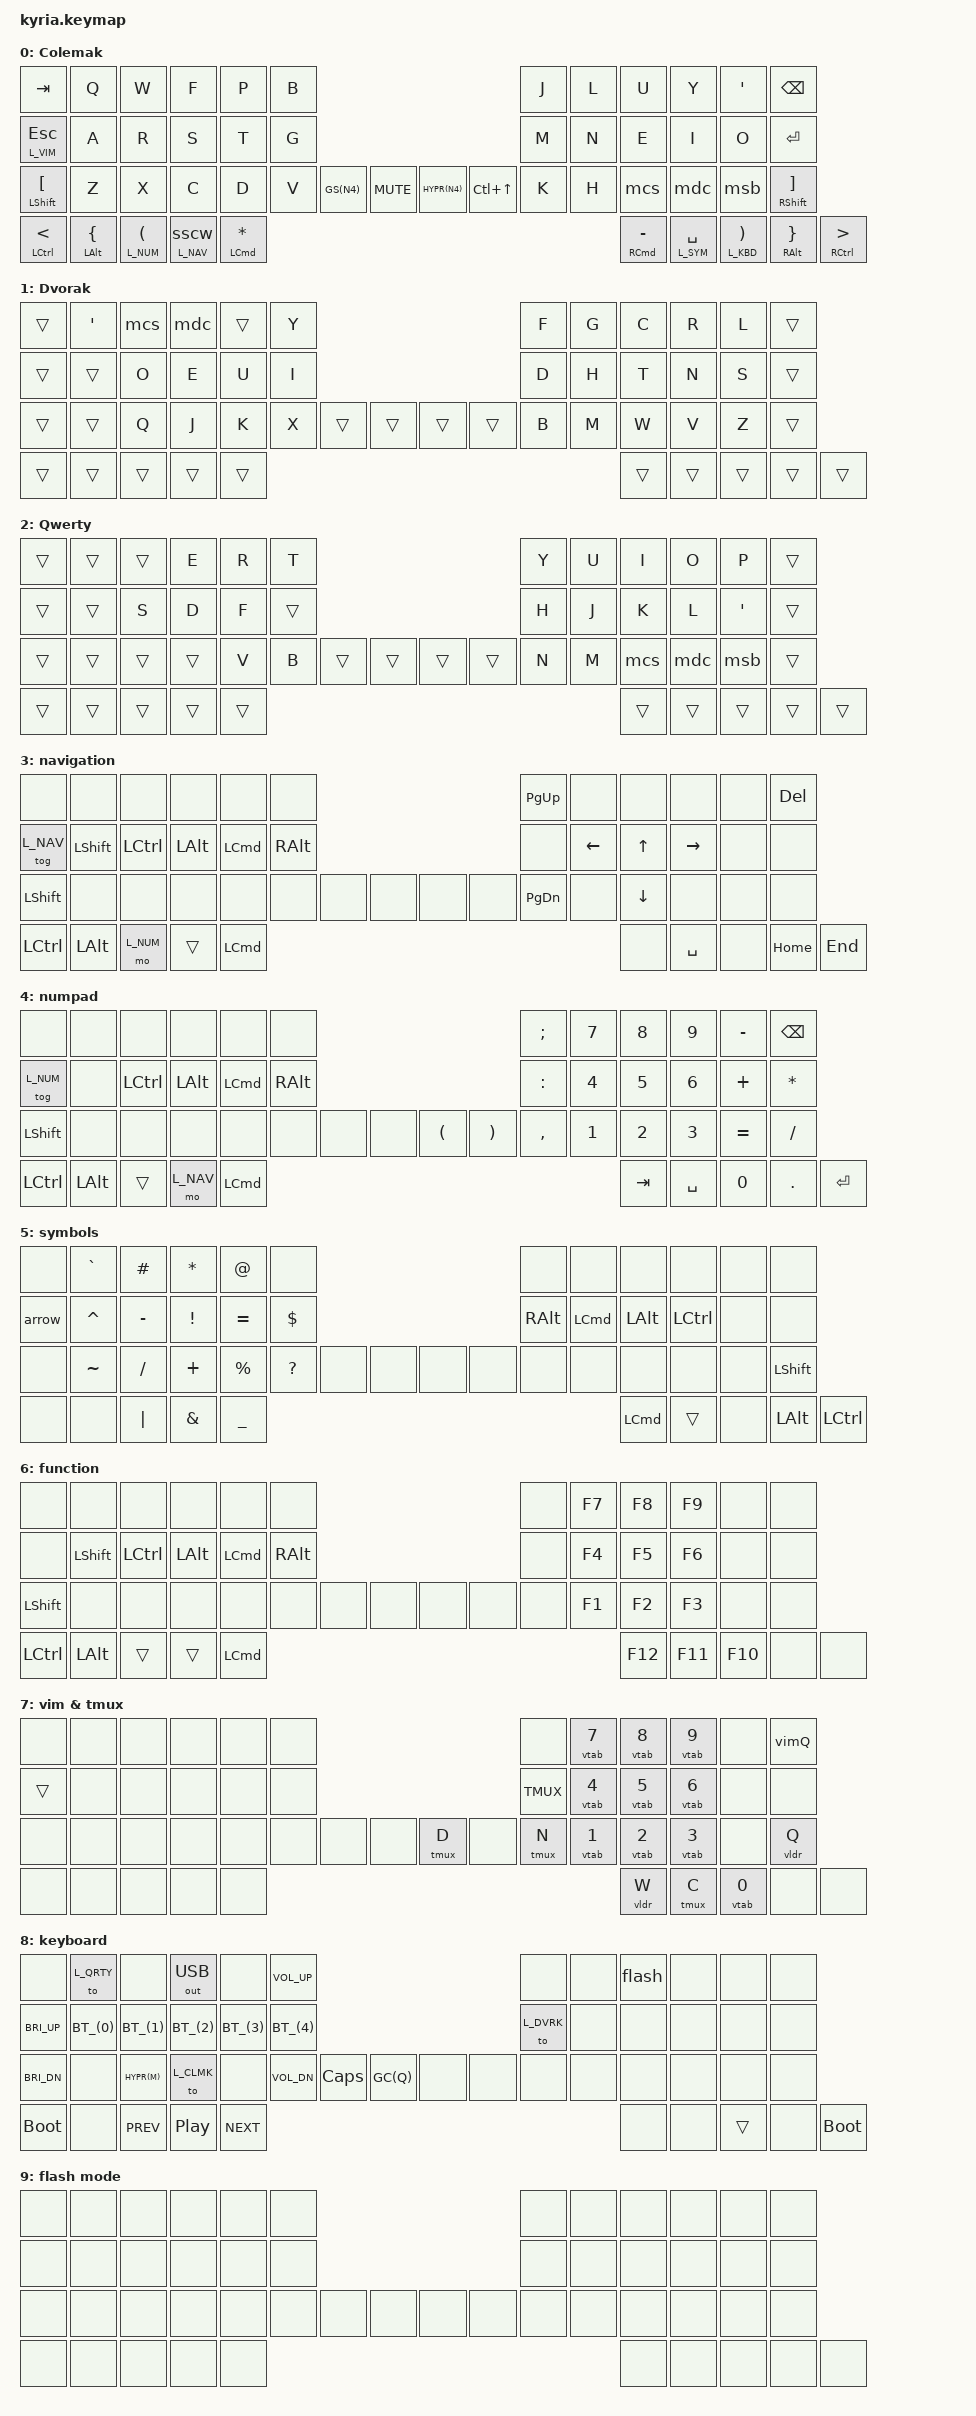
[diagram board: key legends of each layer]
// Kyria rev 3.1 board from splitkb.com
//
// Nice!nano boards on each half, with no rgb strip or oled
//
// Seeed Studio Round Display for XIAO with a Xioa BLE as the central dongle

#include <behaviors.dtsi>
#include <dt-bindings/zmk/bt.h>
#include <dt-bindings/zmk/keys.h>
#include <dt-bindings/zmk/outputs.h>

#define L_CLMK 0
#define L_DVRK 1
#define L_QRTY 2
#define L_NAV  3
#define L_NUM  4
#define L_SYM  5
#define L_FNC  6
#define L_VIM  7
#define L_KBD  8
#define L_BOOT 9

// Make blank keys more inconspicuous
#define X___X &trans
#define ___ &none

// In case you want to change your leader keys
#define TMUX LC(B)
#define VIM SPACE

// Modifier key combinations
#define GC(key) &kp LG(LC(key))
#define GS(key) &kp LG(LS(key))
#define HYPR(key) &kp LG(LA(LC(LS(key))))

// Macro for bluetooth connections
#define BT_(btnum) &bt_key btnum btnum

// Change mod-tap defaults
&mt {
    quick-tap-ms = <200>;
    require-prior-idle-ms = <150>;
    flavor = "tap-preferred";
    tapping-term-ms = <300>;
};

// Change sticky key defaults
&sk {
    release-after-ms = <2000>;
    quick-release;
};

// Change caps word defaults
&caps_word {
    continue-list = <UNDERSCORE MINUS BACKSPACE DEL>;
};

/ {
    behaviors {
        bt_key: bluetooth_key {
            compatible = "zmk,behavior-hold-tap";
            #binding-cells = <2>;
            flavor = "tap-preferred";
            tapping-term-ms = <500>;
            bindings = <&bt_clr>, <&bt_sel>;
        };

        lsscw: layer_sticky_shift_caps_word {
            compatible = "zmk,behavior-hold-tap";
            #binding-cells = <2>;
            flavor = "balanced";
            tapping-term-ms = <200>;
            bindings = <&mo>, <&sscw>;
        };

        mcs: mod_comma_semi {
            compatible = "zmk,behavior-mod-morph";
            #binding-cells = <0>;
            bindings = <&kp COMMA>, <&kp SEMI>;
            mods = <(MOD_LSFT|MOD_RSFT)>;
        };

        mdc: mod_dot_colon {
            compatible = "zmk,behavior-mod-morph";
            #binding-cells = <0>;
            bindings = <&kp DOT>, <&kp COLON>;
            mods = <(MOD_LSFT|MOD_RSFT)>;
        };

        msb: mod_slash_back {
            compatible = "zmk,behavior-mod-morph";
            #binding-cells = <0>;
            bindings = <&kp SLASH>, <&kp BACKSLASH>;
            mods = <(MOD_LSFT|MOD_RSFT)>;
        };

        sscw: sticky_shift_caps_word {
            compatible = "zmk,behavior-mod-morph";
            #binding-cells = <0>;
            bindings = <&sk LSHIFT>, <&caps_word>;
            mods = <(MOD_LSFT|MOD_RSFT)>;
        };
    };

    conditional_layers {
        compatible = "zmk,conditional-layers";
        func_layer {
            if-layers = <L_NAV L_NUM>;
            then-layer = <L_FNC>;
        };
    };

    macros {
        arrow: javascript_arrow_function_macro {
            compatible = "zmk,behavior-macro";
            #binding-cells = <0>;
            bindings = <&kp EQUAL &kp GT &kp SPACE>;
        };

        bt_clr: bluetooth_clear_macro {
            compatible = "zmk,behavior-macro-one-param";
            #binding-cells = <1>;
            bindings =
                <&macro_param_1to1 &bt_sel MACRO_PLACEHOLDER>,
                <&bt BT_CLR>;
        };

        bt_sel: bluetooth_selection_macro {
            compatible = "zmk,behavior-macro-one-param";
            #binding-cells = <1>;
            bindings =
                <&out OUT_BLE>,
                <&macro_param_1to2 &bt BT_SEL MACRO_PLACEHOLDER>;
        };

        flash: dongle_bootloader_macro {
            compatible = "zmk,behavior-macro";
            #binding-cells = <0>;
            bindings = <&to L_BOOT>, <&bootloader>;
        };

        tmux: tmux_prefix_macro {
            compatible = "zmk,behavior-macro-one-param";
            #binding-cells = <1>;
            bindings =
                <&macro_tap &kp TMUX>,
                <&macro_param_1to1 &macro_tap &kp MACRO_PLACEHOLDER>;
        };

        vldr: vim_leader_macro {
            compatible = "zmk,behavior-macro-one-param";
            #binding-cells = <1>;
            bindings =
                <&macro_tap &kp ESC &kp VIM>,
                <&macro_param_1to1 &kp MACRO_PLACEHOLDER>;
        };

        vimQ: vim_hard_quit {
            compatible = "zmk,behavior-macro";
            #binding-cells = <0>;
            bindings = <&macro_tap &kp ESC>, <&kp COLON &kp Q &kp EXCL &kp RET>;
        };

        vtab: vim_tab_macro {
            compatible = "zmk,behavior-macro-one-param";
            #binding-cells = <1>;
            bindings =
                <&macro_tap &kp ESC>,
                <&macro_param_1to1 &kp MACRO_PLACEHOLDER>,
                <&kp G &kp T>;
        };
    };

    keymap {
        compatible = "zmk,keymap";

        colemak {
//                       ┏━━━━━━━━━━━━━━━━━━━━━━━━━┓
            display-name = "Colemak"               ;
//                       ┗━━━━━━━━━━━━━━━━━━━━━━━━━┛
            bindings = <
// ┏━━━━━━━┳━━━━━━━┳━━━━━━━┳━━━━━━━┳━━━━━━━┳━━━━━━━┓                                 ┏━━━━━━━┳━━━━━━━┳━━━━━━━┳━━━━━━━┳━━━━━━━┳━━━━━━━┓
// ┃  TAB  ┃   Q   ┃   W   ┃   F   ┃   P   ┃   B   ┃                                 ┃   J   ┃   L   ┃   U   ┃   Y   ┃  ' "  ┃ BKSPC ┃
    &kp TAB  &kp Q   &kp W   &kp F   &kp P   &kp B                                     &kp J   &kp L   &kp U   &kp Y  &kp SQT &kp BSPC
// ┣━━━━━━━╋━━━━━━━╋━━━━━━━╋━━━━━━━╋━━━━━━━╋━━━━━━━┫                                 ┣━━━━━━━╋━━━━━━━╋━━━━━━━╋━━━━━━━╋━━━━━━━╋━━━━━━━┫
// ┃ESC vim┃   A   ┃   R   ┃   S   ┃   T   ┃   G   ┃                                 ┃   M   ┃   N   ┃   E   ┃   I   ┃   O   ┃ ENTER ┃
&lt L_VIM ESC &kp A  &kp R   &kp S   &kp T   &kp G                                     &kp M   &kp N   &kp E   &kp I   &kp O  &kp RET
// ┣━━━━━━━╋━━━━━━━╋━━━━━━━╋━━━━━━━╋━━━━━━━╋━━━━━━━╋━━━━━━━┳━━━━━━━┓ ┏━━━━━━━┳━━━━━━━╋━━━━━━━╋━━━━━━━╋━━━━━━━╋━━━━━━━╋━━━━━━━╋━━━━━━━┫
// ┃[ shift┃   Z   ┃   X   ┃   C   ┃   D   ┃   V   ┃SCRNSHT┃ MUTE  ┃ ┃LAUNCHP┃MISSION┃   K   ┃   H   ┃  , ;  ┃  . :  ┃  / \  ┃] shift┃
&mt LSHFT LBKT &kp Z &kp X   &kp C   &kp D   &kp V GS(N4) &kp K_MUTE HYPR(N4) &kp LC(UP) &kp K &kp H   &mcs    &mdc    &msb &mt RSHFT RBKT
// ┗━━━━━━━┻━━━━━━━┻━━━┳━━━┻━━━┳━━━┻━━━┳━━━┻━━━┳━━━┻━━━┳━━━┻━━━┳━━━┛ ┗━━━┳━━━┻━━━┳━━━┻━━━┳━━━┻━━━┳━━━┻━━━┳━━━┻━━━┳━━━┻━━━━━━━┻━━━━━━━┛
//                     ┃ < ctrl┃ { opt ┃ ( num ┃ SHIFT ┃ * cmd ┃         ┃ - cmd ┃ SPACE ┃ ) kbd ┃ } opt ┃ > ctrl┃
&mt LCTRL LT &mt LALT LBRC &lt L_NUM LPAR &lsscw L_NAV 0 &mt LCMD STAR &mt RCMD MINUS &lt L_SYM SPC &lt L_KBD RPAR &mt RALT RBRC &mt RCTRL GT
//                     ┗━━━━━━━┻━━━━━━━┻━━━━━━━┫  nav  ┣━━━━━━━┛         ┗━━━━━━━┫  sym  ┣━━━━━━━┻━━━━━━━┻━━━━━━━┛
//                                             ┗━━━━━━━┛                         ┗━━━━━━━┛
            >;
        };

        dvorak {
//                       ┏━━━━━━━━━━━━━━━━━━━━━━━━━┓
            display-name = "Dvorak"                ;
//                       ┗━━━━━━━━━━━━━━━━━━━━━━━━━┛
            bindings = <
// ┏━━━━━━━┳━━━━━━━┳━━━━━━━┳━━━━━━━┳━━━━━━━┳━━━━━━━┓                                 ┏━━━━━━━┳━━━━━━━┳━━━━━━━┳━━━━━━━┳━━━━━━━┳━━━━━━━┓
// ┃  TAB  ┃  ' "  ┃  , ;  ┃  . :  ┃   P   ┃   Y   ┃                                 ┃   F   ┃   G   ┃   C   ┃   R   ┃   L   ┃ BKSPC ┃
     X___X  &kp SQT  &mcs    &mdc    X___X   &kp Y                                     &kp F   &kp G   &kp C   &kp R   &kp L   X___X
// ┣━━━━━━━╋━━━━━━━╋━━━━━━━╋━━━━━━━╋━━━━━━━╋━━━━━━━┫                                 ┣━━━━━━━╋━━━━━━━╋━━━━━━━╋━━━━━━━╋━━━━━━━╋━━━━━━━┫
// ┃ESC vim┃   A   ┃   O   ┃   E   ┃   U   ┃   I   ┃                                 ┃   D   ┃   H   ┃   T   ┃   N   ┃   S   ┃ ENTER ┃
     X___X   X___X   &kp O   &kp E   &kp U   &kp I                                     &kp D   &kp H   &kp T   &kp N   &kp S   X___X
// ┣━━━━━━━╋━━━━━━━╋━━━━━━━╋━━━━━━━╋━━━━━━━╋━━━━━━━╋━━━━━━━┳━━━━━━━┓ ┏━━━━━━━┳━━━━━━━╋━━━━━━━╋━━━━━━━╋━━━━━━━╋━━━━━━━╋━━━━━━━╋━━━━━━━┫
// ┃[ shift┃  / \  ┃   Q   ┃   J   ┃   K   ┃   X   ┃SCRNSHT┃ MUTE  ┃ ┃LAUNCHP┃MISSION┃   B   ┃   M   ┃   W   ┃   V   ┃   Z   ┃] shift┃
     X___X   X___X   &kp Q   &kp J   &kp K   &kp X   X___X   X___X     X___X   X___X   &kp B   &kp M   &kp W   &kp V   &kp Z   X___X
// ┗━━━━━━━┻━━━━━━━┻━━━┳━━━┻━━━┳━━━┻━━━┳━━━┻━━━┳━━━┻━━━┳━━━┻━━━┳━━━┛ ┗━━━┳━━━┻━━━┳━━━┻━━━┳━━━┻━━━┳━━━┻━━━┳━━━┻━━━┳━━━┻━━━━━━━┻━━━━━━━┛
//                     ┃ < ctrl┃ { opt ┃ ( num ┃ SHIFT ┃ * cmd ┃         ┃ - cmd ┃ SPACE ┃ ) kbd ┃ } opt ┃ > ctrl┃
                         X___X   X___X   X___X   X___X   X___X             X___X   X___X   X___X   X___X   X___X
//                     ┗━━━━━━━┻━━━━━━━┻━━━━━━━┫  nav  ┣━━━━━━━┛         ┗━━━━━━━┫  sym  ┣━━━━━━━┻━━━━━━━┻━━━━━━━┛
//                                             ┗━━━━━━━┛                         ┗━━━━━━━┛
            >;
        };

        qwerty {
//                       ┏━━━━━━━━━━━━━━━━━━━━━━━━━┓
            display-name = "Qwerty"                ;
//                       ┗━━━━━━━━━━━━━━━━━━━━━━━━━┛
            bindings = <
// ┏━━━━━━━┳━━━━━━━┳━━━━━━━┳━━━━━━━┳━━━━━━━┳━━━━━━━┓                                 ┏━━━━━━━┳━━━━━━━┳━━━━━━━┳━━━━━━━┳━━━━━━━┳━━━━━━━┓
// ┃  TAB  ┃   Q   ┃   W   ┃   E   ┃   R   ┃   T   ┃                                 ┃   Y   ┃   U   ┃   I   ┃   O   ┃   P   ┃ BKSPC ┃
     X___X   X___X   X___X   &kp E   &kp R   &kp T                                     &kp Y   &kp U   &kp I   &kp O   &kp P   X___X
// ┣━━━━━━━╋━━━━━━━╋━━━━━━━╋━━━━━━━╋━━━━━━━╋━━━━━━━┫                                 ┣━━━━━━━╋━━━━━━━╋━━━━━━━╋━━━━━━━╋━━━━━━━╋━━━━━━━┫
// ┃ESC vim┃   A   ┃   S   ┃   D   ┃   F   ┃   G   ┃                                 ┃   H   ┃   J   ┃   K   ┃   L   ┃  ' "  ┃ ENTER ┃
     X___X   X___X   &kp S   &kp D   &kp F   X___X                                     &kp H   &kp J   &kp K   &kp L  &kp SQT  X___X
// ┣━━━━━━━╋━━━━━━━╋━━━━━━━╋━━━━━━━╋━━━━━━━╋━━━━━━━╋━━━━━━━┳━━━━━━━┓ ┏━━━━━━━┳━━━━━━━╋━━━━━━━╋━━━━━━━╋━━━━━━━╋━━━━━━━╋━━━━━━━╋━━━━━━━┫
// ┃[ shift┃   Z   ┃   X   ┃   C   ┃   V   ┃   B   ┃SCRNSHT┃ MUTE  ┃ ┃LAUNCHP┃MISSION┃   N   ┃   M   ┃  , ;  ┃  . :  ┃  / \  ┃] shift┃
     X___X   X___X   X___X   X___X   &kp V   &kp B   X___X   X___X     X___X   X___X   &kp N   &kp M   &mcs    &mdc    &msb    X___X
// ┗━━━━━━━┻━━━━━━━┻━━━┳━━━┻━━━┳━━━┻━━━┳━━━┻━━━┳━━━┻━━━┳━━━┻━━━┳━━━┛ ┗━━━┳━━━┻━━━┳━━━┻━━━┳━━━┻━━━┳━━━┻━━━┳━━━┻━━━┳━━━┻━━━━━━━┻━━━━━━━┛
//                     ┃ < ctrl┃ { opt ┃ ( num ┃ SHIFT ┃ * cmd ┃         ┃ - cmd ┃ SPACE ┃ ) kbd ┃ } opt ┃ > ctrl┃
                         X___X   X___X   X___X   X___X   X___X             X___X   X___X   X___X   X___X   X___X
//                     ┗━━━━━━━┻━━━━━━━┻━━━━━━━┫  nav  ┣━━━━━━━┛         ┗━━━━━━━┫  sym  ┣━━━━━━━┻━━━━━━━┻━━━━━━━┛
//                                             ┗━━━━━━━┛                         ┗━━━━━━━┛
            >;
        };

        navigation {
//                       ┏━━━━━━━━━━━━━━━━━━━━━━━━━┓
            display-name = "navigation"            ;
//                       ┗━━━━━━━━━━━━━━━━━━━━━━━━━┛
            bindings = <
// ┏━━━━━━━┳━━━━━━━┳━━━━━━━┳━━━━━━━┳━━━━━━━┳━━━━━━━┓                                 ┏━━━━━━━┳━━━━━━━┳━━━━━━━┳━━━━━━━┳━━━━━━━┳━━━━━━━┓
// ┃       ┃       ┃       ┃       ┃       ┃       ┃                                 ┃ PG UP ┃       ┃       ┃       ┃       ┃  DEL  ┃
      ___     ___     ___     ___     ___     ___                                    &kp PG_UP  ___     ___     ___     ___   &kp DEL
// ┣━━━━━━━╋━━━━━━━╋━━━━━━━╋━━━━━━━╋━━━━━━━╋━━━━━━━┫                                 ┣━━━━━━━╋━━━━━━━╋━━━━━━━╋━━━━━━━╋━━━━━━━╋━━━━━━━┫
// ┃ TOGGL ┃ shift ┃  ctrl ┃  opt  ┃  cmd  ┃  alt  ┃                                 ┃       ┃ LEFT  ┃  UP   ┃ RIGHT ┃       ┃       ┃
&tog L_NAV &kp LSHFT &kp LCTRL &kp LALT &kp LCMD &kp RALT                               ___  &kp LEFT &kp UP &kp RIGHT  ___     ___
// ┣━━━━━━━╋━━━━━━━╋━━━━━━━╋━━━━━━━╋━━━━━━━╋━━━━━━━╋━━━━━━━┳━━━━━━━┓ ┏━━━━━━━┳━━━━━━━╋━━━━━━━╋━━━━━━━╋━━━━━━━╋━━━━━━━╋━━━━━━━╋━━━━━━━┫
// ┃       ┃       ┃       ┃       ┃       ┃       ┃       ┃       ┃ ┃       ┃       ┃ PG DN ┃       ┃ DOWN  ┃       ┃       ┃       ┃
   &kp LSHFT  ___     ___     ___     ___     ___     ___     ___       ___     ___  &kp PG_DN  ___  &kp DOWN   ___     ___     ___
// ┗━━━━━━━┻━━━━━━━┻━━━┳━━━┻━━━┳━━━┻━━━┳━━━┻━━━┳━━━┻━━━┳━━━┻━━━┳━━━┛ ┗━━━┳━━━┻━━━┳━━━┻━━━┳━━━┻━━━┳━━━┻━━━┳━━━┻━━━┳━━━┻━━━━━━━┻━━━━━━━┛
//                     ┃       ┃       ┃  fnc  ┃  ###  ┃       ┃         ┃       ┃ SPACE ┃       ┃ HOME  ┃  END  ┃
                    &kp LCTRL &kp LALT &mo L_NUM X___X &kp LCMD             ___   &kp SPC   ___  &kp HOME &kp END
//                     ┗━━━━━━━┻━━━━━━━┻━━━━━━━┫  ###  ┣━━━━━━━┛         ┗━━━━━━━┫       ┣━━━━━━━┻━━━━━━━┻━━━━━━━┛
//                                             ┗━━━━━━━┛                         ┗━━━━━━━┛
            >;
        };

        numpad {
//                       ┏━━━━━━━━━━━━━━━━━━━━━━━━━┓
            display-name = "numpad"                ;
//                       ┗━━━━━━━━━━━━━━━━━━━━━━━━━┛
            bindings = <
// ┏━━━━━━━┳━━━━━━━┳━━━━━━━┳━━━━━━━┳━━━━━━━┳━━━━━━━┓                                 ┏━━━━━━━┳━━━━━━━┳━━━━━━━┳━━━━━━━┳━━━━━━━┳━━━━━━━┓
// ┃       ┃       ┃       ┃       ┃       ┃       ┃                                 ┃   ;   ┃   7   ┃   8   ┃   9   ┃   -   ┃ BKSPC ┃
      ___     ___     ___     ___     ___     ___                                    &kp SEMI &kp N7 &kp N8  &kp N9 &kp MINUS &kp BSPC
// ┣━━━━━━━╋━━━━━━━╋━━━━━━━╋━━━━━━━╋━━━━━━━╋━━━━━━━┫                                 ┣━━━━━━━╋━━━━━━━╋━━━━━━━╋━━━━━━━╋━━━━━━━╋━━━━━━━┫
// ┃ TOGGL ┃       ┃  ctrl ┃  opt  ┃  cmd  ┃  alt  ┃                                 ┃   :   ┃   4   ┃   5   ┃   6   ┃   +   ┃   *   ┃
  &tog L_NUM ___ &kp LCTRL &kp LALT &kp LCMD &kp RALT                                &kp COLON &kp N4 &kp N5  &kp N6 &kp PLUS &kp STAR
// ┣━━━━━━━╋━━━━━━━╋━━━━━━━╋━━━━━━━╋━━━━━━━╋━━━━━━━╋━━━━━━━┳━━━━━━━┓ ┏━━━━━━━┳━━━━━━━╋━━━━━━━╋━━━━━━━╋━━━━━━━╋━━━━━━━╋━━━━━━━╋━━━━━━━┫
// ┃       ┃       ┃       ┃       ┃       ┃       ┃       ┃       ┃ ┃   (   ┃   )   ┃   ,   ┃   1   ┃   2   ┃   3   ┃   =   ┃   /   ┃
   &kp LSHFT  ___     ___     ___     ___     ___     ___     ___   &kp LPAR &kp RPAR &kp COMMA &kp N1 &kp N2 &kp N3 &kp EQUAL &kp SLASH
// ┗━━━━━━━┻━━━━━━━┻━━━┳━━━┻━━━┳━━━┻━━━┳━━━┻━━━┳━━━┻━━━┳━━━┻━━━┳━━━┛ ┗━━━┳━━━┻━━━┳━━━┻━━━┳━━━┻━━━┳━━━┻━━━┳━━━┻━━━┳━━━┻━━━━━━━┻━━━━━━━┛
//                     ┃       ┃       ┃  ###  ┃       ┃       ┃         ┃  TAB  ┃ SPACE ┃   0   ┃   .   ┃ ENTER ┃
                      &kp LCTRL &kp LALT X___X &mo L_NAV &kp LCMD         &kp TAB &kp SPC  &kp N0 &kp DOT &kp RET
//                     ┗━━━━━━━┻━━━━━━━┻━━━━━━━┫  fnc  ┣━━━━━━━┛         ┗━━━━━━━┫       ┣━━━━━━━┻━━━━━━━┻━━━━━━━┛
//                                             ┗━━━━━━━┛                         ┗━━━━━━━┛
            >;
        };

        symbols {
//                       ┏━━━━━━━━━━━━━━━━━━━━━━━━━┓
            display-name = "symbols"               ;
//                       ┗━━━━━━━━━━━━━━━━━━━━━━━━━┛
            bindings = <
// ┏━━━━━━━┳━━━━━━━┳━━━━━━━┳━━━━━━━┳━━━━━━━┳━━━━━━━┓                                 ┏━━━━━━━┳━━━━━━━┳━━━━━━━┳━━━━━━━┳━━━━━━━┳━━━━━━━┓
// ┃       ┃   `   ┃   #   ┃   *   ┃   @   ┃       ┃                                 ┃       ┃       ┃       ┃       ┃       ┃       ┃
      ___  &kp GRAVE &kp HASH &kp STAR &kp AT ___                                       ___     ___     ___     ___     ___     ___
// ┣━━━━━━━╋━━━━━━━╋━━━━━━━╋━━━━━━━╋━━━━━━━╋━━━━━━━┫                                 ┣━━━━━━━╋━━━━━━━╋━━━━━━━╋━━━━━━━╋━━━━━━━╋━━━━━━━┫
// ┃  =>   ┃   ^   ┃   -   ┃   !   ┃   =   ┃   $   ┃                                 ┃  alt  ┃  cmd  ┃  opt  ┃ ctrl  ┃       ┃       ┃
&arrow &kp CARET &kp MINUS &kp EXCL &kp EQUAL &kp DLLR                               &kp RALT &kp LCMD &kp LALT &kp LCTRL ___   ___
// ┣━━━━━━━╋━━━━━━━╋━━━━━━━╋━━━━━━━╋━━━━━━━╋━━━━━━━╋━━━━━━━┳━━━━━━━┓ ┏━━━━━━━┳━━━━━━━╋━━━━━━━╋━━━━━━━╋━━━━━━━╋━━━━━━━╋━━━━━━━╋━━━━━━━┫
// ┃       ┃   ~   ┃   /   ┃   +   ┃   %   ┃   ?   ┃       ┃       ┃ ┃       ┃       ┃       ┃       ┃       ┃       ┃       ┃       ┃
    ___ &kp TILDE &kp SLASH &kp PLUS &kp PRCNT &kp QMARK ___  ___       ___     ___     ___     ___     ___     ___     ___  &kp LSHFT
// ┗━━━━━━━┻━━━━━━━┻━━━┳━━━┻━━━┳━━━┻━━━┳━━━┻━━━┳━━━┻━━━┳━━━┻━━━┳━━━┛ ┗━━━┳━━━┻━━━┳━━━┻━━━┳━━━┻━━━┳━━━┻━━━┳━━━┻━━━┳━━━┻━━━━━━━┻━━━━━━━┛
//                     ┃       ┃       ┃   |   ┃   &   ┃   _   ┃         ┃       ┃  ###  ┃       ┃       ┃       ┃
                          ___     ___ &kp PIPE &kp AMPS &kp UNDER        &kp LCMD  X___X    ___  &kp LALT &kp LCTRL
//                     ┗━━━━━━━┻━━━━━━━┻━━━━━━━┫       ┣━━━━━━━┛         ┗━━━━━━━┫  ###  ┣━━━━━━━┻━━━━━━━┻━━━━━━━┛
//                                             ┗━━━━━━━┛                         ┗━━━━━━━┛
            >;
        };

        function {
//                       ┏━━━━━━━━━━━━━━━━━━━━━━━━━┓
            display-name = "function"              ;
//                       ┗━━━━━━━━━━━━━━━━━━━━━━━━━┛
            bindings = <
// ┏━━━━━━━┳━━━━━━━┳━━━━━━━┳━━━━━━━┳━━━━━━━┳━━━━━━━┓                                 ┏━━━━━━━┳━━━━━━━┳━━━━━━━┳━━━━━━━┳━━━━━━━┳━━━━━━━┓
// ┃       ┃       ┃       ┃       ┃       ┃       ┃                                 ┃       ┃  F7   ┃  F8   ┃  F9   ┃       ┃       ┃
      ___     ___     ___     ___     ___     ___                                       ___    &kp F7  &kp F8  &kp F9   ___     ___
// ┣━━━━━━━╋━━━━━━━╋━━━━━━━╋━━━━━━━╋━━━━━━━╋━━━━━━━┫                                 ┣━━━━━━━╋━━━━━━━╋━━━━━━━╋━━━━━━━╋━━━━━━━╋━━━━━━━┫
// ┃       ┃ shift ┃  ctrl ┃  opt  ┃  cmd  ┃  alt  ┃                                 ┃       ┃  F4   ┃  F5   ┃  F6   ┃       ┃       ┃
   ___ &kp LSHFT &kp LCTRL &kp LALT &kp LCMD &kp RALT                                   ___    &kp F4  &kp F5  &kp F6   ___     ___
// ┣━━━━━━━╋━━━━━━━╋━━━━━━━╋━━━━━━━╋━━━━━━━╋━━━━━━━╋━━━━━━━┳━━━━━━━┓ ┏━━━━━━━┳━━━━━━━╋━━━━━━━╋━━━━━━━╋━━━━━━━╋━━━━━━━╋━━━━━━━╋━━━━━━━┫
// ┃       ┃       ┃       ┃       ┃       ┃       ┃       ┃       ┃ ┃       ┃       ┃       ┃  F1   ┃  F2   ┃  F3   ┃       ┃       ┃
   &kp LSHFT  ___     ___     ___     ___     ___     ___     ___       ___     ___     ___    &kp F1  &kp F2  &kp F3   ___     ___
// ┗━━━━━━━┻━━━━━━━┻━━━┳━━━┻━━━┳━━━┻━━━┳━━━┻━━━┳━━━┻━━━┳━━━┻━━━┳━━━┛ ┗━━━┳━━━┻━━━┳━━━┻━━━┳━━━┻━━━┳━━━┻━━━┳━━━┻━━━┳━━━┻━━━━━━━┻━━━━━━━┛
//                     ┃       ┃       ┃  ###  ┃  ###  ┃       ┃         ┃  F12  ┃  F11  ┃  F10  ┃       ┃       ┃
                      &kp LCTRL &kp LALT X___X   X___X &kp LCMD           &kp F12 &kp F11 &kp F10   ___     ___
//                     ┗━━━━━━━┻━━━━━━━┻━━━━━━━┫  ###  ┣━━━━━━━┛         ┗━━━━━━━┫       ┣━━━━━━━┻━━━━━━━┻━━━━━━━┛
//                                             ┗━━━━━━━┛                         ┗━━━━━━━┛
            >;
        };


        vim {
//                       ┏━━━━━━━━━━━━━━━━━━━━━━━━━┓
            display-name = "vim & tmux"            ;
//                       ┗━━━━━━━━━━━━━━━━━━━━━━━━━┛
            bindings = <
// ┏━━━━━━━┳━━━━━━━┳━━━━━━━┳━━━━━━━┳━━━━━━━┳━━━━━━━┓                                 ┏━━━━━━━┳━━━━━━━┳━━━━━━━┳━━━━━━━┳━━━━━━━┳━━━━━━━┓
// ┃       ┃       ┃       ┃       ┃       ┃       ┃                                 ┃       ┃ tab 7 ┃ tab 8 ┃ tab 9 ┃       ┃ quit! ┃
      ___     ___     ___     ___     ___     ___                                       ___ &vtab N7 &vtab N8 &vtab N9  ___    &vimQ
// ┣━━━━━━━╋━━━━━━━╋━━━━━━━╋━━━━━━━╋━━━━━━━╋━━━━━━━┫                                 ┣━━━━━━━╋━━━━━━━╋━━━━━━━╋━━━━━━━╋━━━━━━━╋━━━━━━━┫
// ┃  ###  ┃       ┃       ┃       ┃       ┃       ┃                                 ┃ tmux- ┃ tab 4 ┃ tab 5 ┃ tab 6 ┃       ┃       ┃
     X___X    ___     ___     ___     ___     ___                                   &kp TMUX &vtab N4 &vtab N5 &vtab N6 ___     ___
// ┣━━━━━━━╋━━━━━━━╋━━━━━━━╋━━━━━━━╋━━━━━━━╋━━━━━━━╋━━━━━━━┳━━━━━━━┓ ┏━━━━━━━┳━━━━━━━╋━━━━━━━╋━━━━━━━╋━━━━━━━╋━━━━━━━╋━━━━━━━╋━━━━━━━┫
// ┃       ┃       ┃       ┃       ┃       ┃       ┃       ┃       ┃ ┃ t bye ┃       ┃ t tab ┃ tab 1 ┃ tab 2 ┃ tab 3 ┃       ┃ exit  ┃
      ___     ___     ___     ___     ___     ___     ___     ___     &tmux D   ___  &tmux N &vtab N1 &vtab N2 &vtab N3 ___   &vldr Q
// ┗━━━━━━━┻━━━━━━━┻━━━┳━━━┻━━━┳━━━┻━━━┳━━━┻━━━┳━━━┻━━━┳━━━┻━━━┳━━━┛ ┗━━━┳━━━┻━━━┳━━━┻━━━┳━━━┻━━━┳━━━┻━━━┳━━━┻━━━┳━━━┻━━━━━━━┻━━━━━━━┛
//                     ┃       ┃       ┃       ┃       ┃       ┃         ┃ save  ┃ tmux  ┃ tname ┃       ┃       ┃
                          ___     ___     ___     ___     ___             &vldr W &tmux C &vtab N0  ___     ___
//                     ┗━━━━━━━┻━━━━━━━┻━━━━━━━┫       ┣━━━━━━━┛         ┗━━━━━━━┫  new  ┣━━━━━━━┻━━━━━━━┻━━━━━━━┛
//                                             ┗━━━━━━━┛                         ┗━━━━━━━┛
            >;
        };

        keyboard {
//                       ┏━━━━━━━━━━━━━━━━━━━━━━━━━┓
            display-name = "keyboard"              ;
//                       ┗━━━━━━━━━━━━━━━━━━━━━━━━━┛
            bindings = <
// ┏━━━━━━━┳━━━━━━━┳━━━━━━━┳━━━━━━━┳━━━━━━━┳━━━━━━━┓                                 ┏━━━━━━━┳━━━━━━━┳━━━━━━━┳━━━━━━━┳━━━━━━━┳━━━━━━━┓
// ┃       ┃ qwrty ┃       ┃  USB  ┃       ┃ vol + ┃                                 ┃       ┃       ┃ dongl ┃       ┃       ┃       ┃
      ___ &to L_QRTY  ___ &out OUT_USB ___ &kp C_VOL_UP                                 ___     ___   &flash    ___     ___     ___
// ┣━━━━━━━╋━━━━━━━╋━━━━━━━╋━━━━━━━╋━━━━━━━╋━━━━━━━┫                                 ┣━━━━━━━╋━━━━━━━╋━━━━━━━╋━━━━━━━╋━━━━━━━╋━━━━━━━┫
// ┃ brt + ┃  BT1  ┃  BT2  ┃  BT3  ┃  BT4  ┃  BT5  ┃                                 ┃ dvork ┃       ┃       ┃       ┃       ┃       ┃
&kp C_BRI_UP BT_(0)  BT_(1)  BT_(2)  BT_(3)  BT_(4)                                 &to L_DVRK  ___     ___     ___     ___     ___
// ┣━━━━━━━╋━━━━━━━╋━━━━━━━╋━━━━━━━╋━━━━━━━╋━━━━━━━╋━━━━━━━┳━━━━━━━┓ ┏━━━━━━━┳━━━━━━━╋━━━━━━━╋━━━━━━━╋━━━━━━━╋━━━━━━━╋━━━━━━━╋━━━━━━━┫
// ┃ brt - ┃       ┃micmute┃ colmk ┃       ┃ vol - ┃CAPSLOK┃scrnlok┃ ┃       ┃       ┃       ┃       ┃       ┃       ┃       ┃       ┃
&kp C_BRI_DN ___ HYPR(M) &to L_CLMK ___ &kp C_VOL_DN &kp CAPSLOCK GC(Q) ___     ___     ___     ___     ___     ___     ___     ___
// ┗━━━━━━━┻━━━━━━━┻━━━┳━━━┻━━━┳━━━┻━━━┳━━━┻━━━┳━━━┻━━━┳━━━┻━━━┳━━━┛ ┗━━━┳━━━┻━━━┳━━━┻━━━┳━━━┻━━━┳━━━┻━━━┳━━━┻━━━┳━━━┻━━━━━━━┻━━━━━━━┛
//                     ┃ flash ┃       ┃  prev ┃  play ┃  next ┃         ┃       ┃       ┃  ###  ┃       ┃ flash ┃
                      &bootloader ___ &kp C_PREV &kp C_PLAY_PAUSE &kp C_NEXT ___    ___    X___X    ___ &bootloader
//                     ┗━━━━━━━┻━━━━━━━┻━━━━━━━┫ pause ┣━━━━━━━┛         ┗━━━━━━━┫       ┣━━━━━━━┻━━━━━━━┻━━━━━━━┛
//                                             ┗━━━━━━━┛                         ┗━━━━━━━┛
            >;
        };

        boot {
//                       ┏━━━━━━━━━━━━━━━━━━━━━━━━━┓
            display-name = "flash mode"            ;
//                       ┗━━━━━━━━━━━━━━━━━━━━━━━━━┛
            bindings = <
// ┏━━━━━━━┳━━━━━━━┳━━━━━━━┳━━━━━━━┳━━━━━━━┳━━━━━━━┓                                 ┏━━━━━━━┳━━━━━━━┳━━━━━━━┳━━━━━━━┳━━━━━━━┳━━━━━━━┓
// ┃       ┃       ┃       ┃       ┃       ┃       ┃                                 ┃       ┃       ┃       ┃       ┃       ┃       ┃
      ___     ___     ___     ___     ___     ___                                       ___     ___     ___     ___     ___     ___
// ┣━━━━━━━╋━━━━━━━╋━━━━━━━╋━━━━━━━╋━━━━━━━╋━━━━━━━┫                                 ┣━━━━━━━╋━━━━━━━╋━━━━━━━╋━━━━━━━╋━━━━━━━╋━━━━━━━┫
// ┃       ┃       ┃       ┃       ┃       ┃       ┃                                 ┃       ┃       ┃       ┃       ┃       ┃       ┃
      ___     ___     ___     ___     ___     ___                                       ___     ___     ___     ___     ___     ___
// ┣━━━━━━━╋━━━━━━━╋━━━━━━━╋━━━━━━━╋━━━━━━━╋━━━━━━━╋━━━━━━━┳━━━━━━━┓ ┏━━━━━━━┳━━━━━━━╋━━━━━━━╋━━━━━━━╋━━━━━━━╋━━━━━━━╋━━━━━━━╋━━━━━━━┫
// ┃       ┃       ┃       ┃       ┃       ┃       ┃       ┃       ┃ ┃       ┃       ┃       ┃       ┃       ┃       ┃       ┃       ┃
      ___     ___     ___     ___     ___     ___     ___     ___       ___     ___     ___     ___     ___     ___     ___     ___
// ┗━━━━━━━┻━━━━━━━┻━━━┳━━━┻━━━┳━━━┻━━━┳━━━┻━━━┳━━━┻━━━┳━━━┻━━━┳━━━┛ ┗━━━┳━━━┻━━━┳━━━┻━━━┳━━━┻━━━┳━━━┻━━━┳━━━┻━━━┳━━━┻━━━━━━━┻━━━━━━━┛
//                     ┃       ┃       ┃       ┃       ┃       ┃         ┃       ┃       ┃       ┃       ┃       ┃
                          ___     ___     ___     ___     ___               ___     ___     ___     ___     ___
//                     ┗━━━━━━━┻━━━━━━━┻━━━━━━━┫       ┣━━━━━━━┛         ┗━━━━━━━┫       ┣━━━━━━━┻━━━━━━━┻━━━━━━━┛
//                                             ┗━━━━━━━┛                         ┗━━━━━━━┛
            >;
        };
    };
};

// vim: expandtab softtabstop=4 shiftwidth=4 filetype=devicetree
